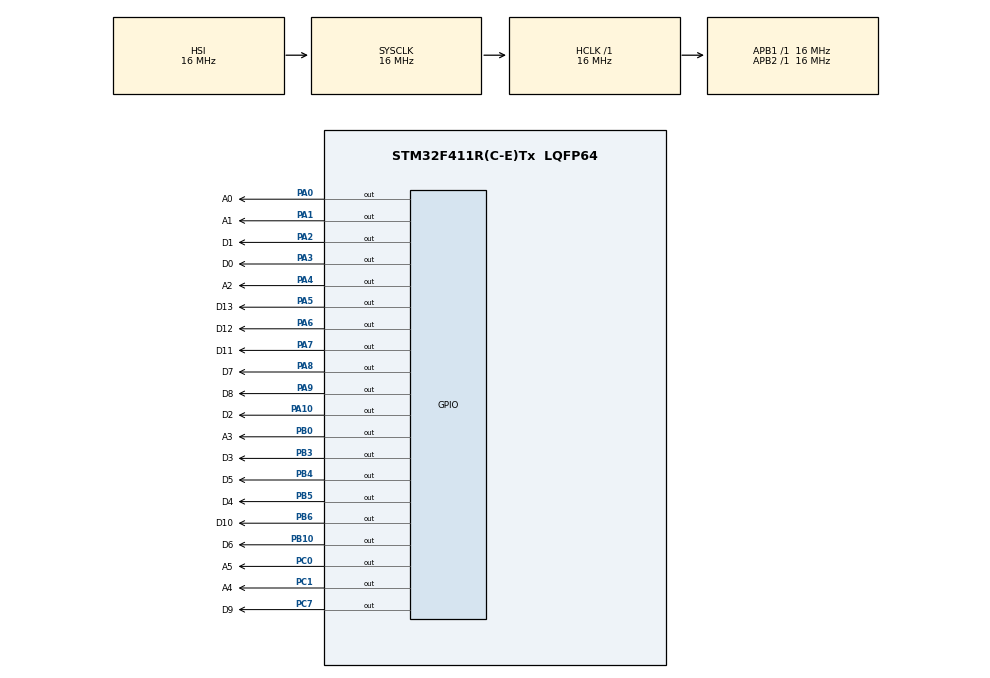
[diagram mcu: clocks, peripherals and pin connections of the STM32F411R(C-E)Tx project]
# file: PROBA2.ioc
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Mcu.Family=STM32F4
RCC.CortexFreq_Value=16000000
PA9.GPIO_Label=D8
PC0.GPIO_Label=A5
PA6.GPIO_Label=D12
PB0.GPIO_Label=A3
PB6.GPIO_Label=D10
PC0.Signal=GPIO_Output
ProjectManager.StackSize=0x400
PA0-WKUP.GPIO_Label=A0
PA0-WKUP.Signal=GPIO_Output
PA8.GPIO_Label=D7
ProjectManager.TargetToolchain=TrueSTUDIO
PB10.GPIO_Label=D6
PA9.Signal=GPIO_Output
PB6.Signal=GPIO_Output
PC7.Signal=GPIO_Output
RCC.LSE_VALUE=32768
PA1.Signal=GPIO_Output
RCC.AHBFreq_Value=16000000
PB10.Signal=GPIO_Output
PA5.Signal=GPIO_Output
RCC.HSE_VALUE=25000000
board=custom
RCC.VCOOutputFreq_Value=192000000
RCC.APB2Freq_Value=16000000
PB4.GPIO_Label=D5
PC1.GPIO_Label=A4
PA1.GPIO_Label=A1
PA10.GPIO_Label=D2
PA8.Signal=GPIO_Output
Mcu.Name=STM32F411R(C-E)Tx
PA2.Signal=GPIO_Output
PC7.GPIO_Label=D9
PB3.Signal=GPIO_Output
PA4.Signal=GPIO_Output
RCC.SYSCLKFreq_VALUE=16000000
Mcu.Package=LQFP64
PB5.Signal=GPIO_Output
PA6.Signal=GPIO_Output
PA7.GPIO_Label=D11
PA5.GPIO_Label=D13
PA2.GPIO_Label=D1
PA10.Signal=GPIO_Output
ProjectManager.HeapSize=0x200
RCC.HSI_VALUE=16000000
NVIC.PriorityGroup=NVIC_PRIORITYGROUP_4
PB5.GPIO_Label=D4
RCC.APB1Freq_Value=16000000
PB0.Signal=GPIO_Output
PA4.GPIO_Label=A2
PC1.Signal=GPIO_Output
PB4.Signal=GPIO_Output
PA3.GPIO_Label=D0
PA3.Signal=GPIO_Output
PA7.Signal=GPIO_Output
PB3.GPIO_Label=D3

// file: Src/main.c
/* USER CODE BEGIN Header */
/**
  ******************************************************************************
  * @file           : main.c
  * @brief          : Main program body
  ******************************************************************************
  * @attention
  *
  * <h2><center>&copy; Copyright (c) 2020 STMicroelectronics.
  * All rights reserved.</center></h2>
  *
  * This software component is licensed by ST under BSD 3-Clause license,
  * the "License"; You may not use this file except in compliance with the
  * License. You may obtain a copy of the License at:
  *                        opensource.org/licenses/BSD-3-Clause
  *
  ******************************************************************************
  */
/* USER CODE END Header */

#include "main.h"

void SystemClock_Config(void);
static void MX_GPIO_Init(void);

int main(void)
{

  /* MCU Configuration--------------------------------------------------------*/

  /* Reset of all peripherals, Initializes the Flash interface and the Systick. */
  HAL_Init();

  /* Configure the system clock */
  SystemClock_Config();

  /* Initialize all configured peripherals */
  MX_GPIO_Init();
  /* USER CODE BEGIN 2 */
  HAL_GPIO_WritePin(A0_GPIO_Port,A0_Pin,1);

  /* USER CODE END 2 */

  /* Infinite loop */
  while (1)
  {

  }
}

void SystemClock_Config(void)
{
  RCC_OscInitTypeDef RCC_OscInitStruct = {0};
  RCC_ClkInitTypeDef RCC_ClkInitStruct = {0};

  /** Configure the main internal regulator output voltage
  */
  __HAL_RCC_PWR_CLK_ENABLE();
  __HAL_PWR_VOLTAGESCALING_CONFIG(PWR_REGULATOR_VOLTAGE_SCALE1);
  /** Initializes the CPU, AHB and APB busses clocks
  */
  RCC_OscInitStruct.OscillatorType = RCC_OSCILLATORTYPE_HSI;
  RCC_OscInitStruct.HSIState = RCC_HSI_ON;
  RCC_OscInitStruct.HSICalibrationValue = RCC_HSICALIBRATION_DEFAULT;
  RCC_OscInitStruct.PLL.PLLState = RCC_PLL_NONE;
  if (HAL_RCC_OscConfig(&RCC_OscInitStruct) != HAL_OK)
  {
    Error_Handler();
  }
  /** Initializes the CPU, AHB and APB busses clocks
  */
  RCC_ClkInitStruct.ClockType = RCC_CLOCKTYPE_HCLK|RCC_CLOCKTYPE_SYSCLK
                              |RCC_CLOCKTYPE_PCLK1|RCC_CLOCKTYPE_PCLK2;
  RCC_ClkInitStruct.SYSCLKSource = RCC_SYSCLKSOURCE_HSI;
  RCC_ClkInitStruct.AHBCLKDivider = RCC_SYSCLK_DIV1;
  RCC_ClkInitStruct.APB1CLKDivider = RCC_HCLK_DIV1;
  RCC_ClkInitStruct.APB2CLKDivider = RCC_HCLK_DIV1;

  if (HAL_RCC_ClockConfig(&RCC_ClkInitStruct, FLASH_LATENCY_0) != HAL_OK)
  {
    Error_Handler();
  }
}

static void MX_GPIO_Init(void)
{
  GPIO_InitTypeDef GPIO_InitStruct = {0};

  /* GPIO Ports Clock Enable */
  __HAL_RCC_GPIOC_CLK_ENABLE();
  __HAL_RCC_GPIOA_CLK_ENABLE();
  __HAL_RCC_GPIOB_CLK_ENABLE();

  /*Configure GPIO pin Output Level */
  HAL_GPIO_WritePin(GPIOC, A5_Pin|A4_Pin|D9_Pin, GPIO_PIN_RESET);

  /*Configure GPIO pin Output Level */
  HAL_GPIO_WritePin(GPIOA, A0_Pin|A1_Pin|D1_Pin|D0_Pin
                          |A2_Pin|D13_Pin|D12_Pin|D11_Pin
                          |D7_Pin|D8_Pin|D2_Pin, GPIO_PIN_RESET);

  /*Configure GPIO pin Output Level */
  HAL_GPIO_WritePin(GPIOB, A3_Pin|D6_Pin|D3_Pin|D5_Pin
                          |D4_Pin|D10_Pin, GPIO_PIN_RESET);

  /*Configure GPIO pins : A5_Pin A4_Pin D9_Pin */
  GPIO_InitStruct.Pin = A5_Pin|A4_Pin|D9_Pin;
  GPIO_InitStruct.Mode = GPIO_MODE_OUTPUT_PP;
  GPIO_InitStruct.Pull = GPIO_NOPULL;
  GPIO_InitStruct.Speed = GPIO_SPEED_FREQ_LOW;
  HAL_GPIO_Init(GPIOC, &GPIO_InitStruct);

  /*Configure GPIO pins : A0_Pin A1_Pin D1_Pin D0_Pin
                           A2_Pin D13_Pin D12_Pin D11_Pin
                           D7_Pin D8_Pin D2_Pin */
  GPIO_InitStruct.Pin = A0_Pin|A1_Pin|D1_Pin|D0_Pin
                          |A2_Pin|D13_Pin|D12_Pin|D11_Pin
                          |D7_Pin|D8_Pin|D2_Pin;
  GPIO_InitStruct.Mode = GPIO_MODE_OUTPUT_PP;
  GPIO_InitStruct.Pull = GPIO_NOPULL;
  GPIO_InitStruct.Speed = GPIO_SPEED_FREQ_LOW;
  HAL_GPIO_Init(GPIOA, &GPIO_InitStruct);

  /*Configure GPIO pins : A3_Pin D6_Pin D3_Pin D5_Pin
                           D4_Pin D10_Pin */
  GPIO_InitStruct.Pin = A3_Pin|D6_Pin|D3_Pin|D5_Pin
                          |D4_Pin|D10_Pin;
  GPIO_InitStruct.Mode = GPIO_MODE_OUTPUT_PP;
  GPIO_InitStruct.Pull = GPIO_NOPULL;
  GPIO_InitStruct.Speed = GPIO_SPEED_FREQ_LOW;
  HAL_GPIO_Init(GPIOB, &GPIO_InitStruct);

}

void Error_Handler(void)
{
}

/************************ (C) COPYRIGHT STMicroelectronics *****END OF FILE****/
